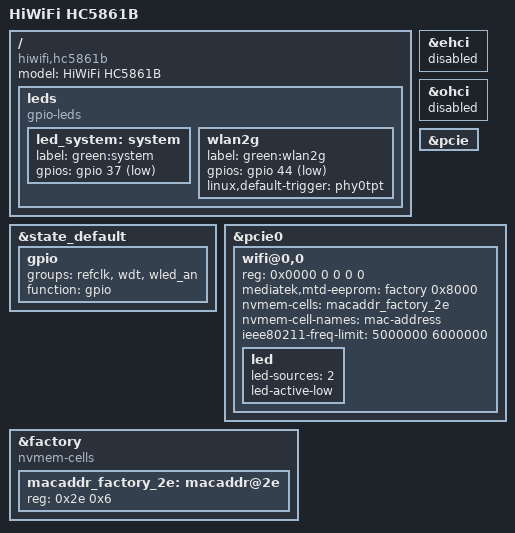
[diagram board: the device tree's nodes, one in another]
#include "mt7628an_hiwifi_hc5x61a.dtsi"

/ {
	compatible = "hiwifi,hc5861b", "mediatek,mt7628an-soc";
	model = "HiWiFi HC5861B";

	leds {
		compatible = "gpio-leds";

		led_system: system {
			label = "green:system";
			gpios = <&gpio 37 GPIO_ACTIVE_LOW>;
		};

		wlan2g {
			label = "green:wlan2g";
			gpios = <&gpio 44 GPIO_ACTIVE_LOW>;
			linux,default-trigger = "phy0tpt";
		};
	};
};

&state_default {
	gpio {
		groups = "refclk", "wdt", "wled_an";
		function = "gpio";
	};
};

&ehci {
	status = "disabled";
};

&ohci {
	status = "disabled";
};

&pcie {
	status = "okay";
};

&pcie0 {
	wifi@0,0 {
		reg = <0x0000 0 0 0 0>;
		mediatek,mtd-eeprom = <&factory 0x8000>;
		nvmem-cells = <&macaddr_factory_2e>;
		nvmem-cell-names = "mac-address";
		ieee80211-freq-limit = <5000000 6000000>;

		led {
			led-sources = <2>;
			led-active-low;
		};
	};
};

&factory {
	compatible = "nvmem-cells";
	#address-cells = <1>;
	#size-cells = <1>;

	macaddr_factory_2e: macaddr@2e {
		reg = <0x2e 0x6>;
	};
};
